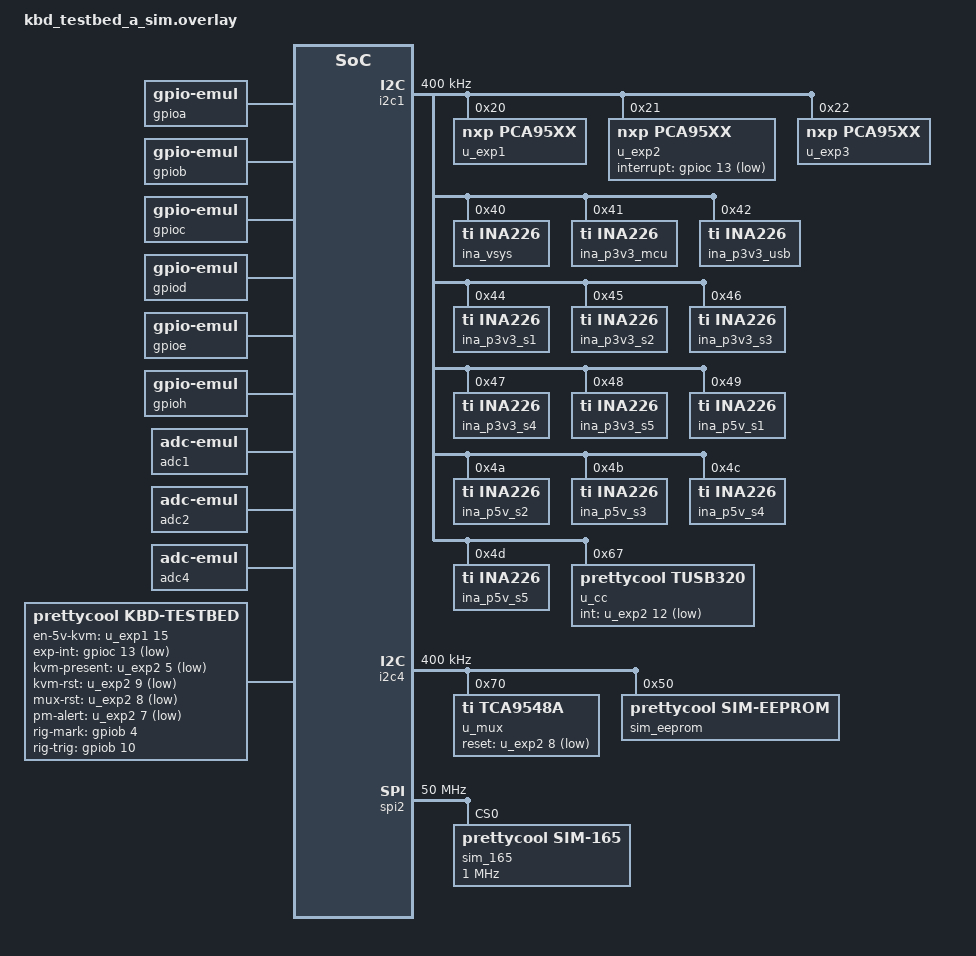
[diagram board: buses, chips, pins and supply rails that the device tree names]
/* GENERATED by keyboard/firmware/boards/gen_board.py from keyboard/hardware/design/nets.py
 * and the SPEC constants in that script. Do not edit: change nets.py (or the script), regenerate.
 * nets.py rev A-testbed 2026-11-27; map hash 10b5eaea9fcebc38.
 *
 * native_sim overlay: kbd_testbed_a's nodes on emulated controllers, for the bring-up app's simulated board
 * (keyboard/firmware/bringup/sim). Register models stand in for the parts: this tests firmware logic, not the
 * hardware. SPDX-License-Identifier: Apache-2.0
 */

#include <zephyr/dt-bindings/adc/adc.h>
#include <zephyr/dt-bindings/gpio/gpio.h>
#include <zephyr/dt-bindings/i2c/i2c.h>

/ {
	gpioa: sim_gpio_a {
		compatible = "zephyr,gpio-emul";
		rising-edge;
		falling-edge;
		high-level;
		low-level;
		gpio-controller;
		#gpio-cells = <2>;
		ngpios = <16>;
		status = "okay";
	};

	gpiob: sim_gpio_b {
		compatible = "zephyr,gpio-emul";
		rising-edge;
		falling-edge;
		high-level;
		low-level;
		gpio-controller;
		#gpio-cells = <2>;
		ngpios = <16>;
		status = "okay";
	};

	gpioc: sim_gpio_c {
		compatible = "zephyr,gpio-emul";
		rising-edge;
		falling-edge;
		high-level;
		low-level;
		gpio-controller;
		#gpio-cells = <2>;
		ngpios = <16>;
		status = "okay";
	};

	gpiod: sim_gpio_d {
		compatible = "zephyr,gpio-emul";
		rising-edge;
		falling-edge;
		high-level;
		low-level;
		gpio-controller;
		#gpio-cells = <2>;
		ngpios = <16>;
		status = "okay";
	};

	gpioe: sim_gpio_e {
		compatible = "zephyr,gpio-emul";
		rising-edge;
		falling-edge;
		high-level;
		low-level;
		gpio-controller;
		#gpio-cells = <2>;
		ngpios = <16>;
		status = "okay";
	};

	gpioh: sim_gpio_h {
		compatible = "zephyr,gpio-emul";
		rising-edge;
		falling-edge;
		high-level;
		low-level;
		gpio-controller;
		#gpio-cells = <2>;
		ngpios = <16>;
		status = "okay";
	};

	i2c1: i2c@71000 {
		compatible = "zephyr,i2c-emul-controller";
		reg = <0x71000 4>;
		clock-frequency = <I2C_BITRATE_FAST>;
		#address-cells = <1>;
		#size-cells = <0>;
		#forward-cells = <1>;
		status = "okay";

		/* U_EXP1 TCA9535 (rail enables, bus-switch enables). Restored outputs 0xFFFF, output register 0x7C00, configuration
		 * 0x0000. nxp,pca95xx with neither has-pud nor has-interrupt-mask-reg (SPEC §8.4). */
		u_exp1: gpio@20 {
			compatible = "nxp,pca95xx";
			reg = <0x20>;
			gpio-controller;
			#gpio-cells = <2>;
			ngpios = <16>;
		};

		/* U_EXP2 TCA9535 (PRESENT_N, faults, alerts, mux and KVM resets, the USB-C detect interrupt). Restored outputs 0x0300, output register 0xFDFF, configuration
		 * 0xFCFF. nxp,pca95xx with neither has-pud nor has-interrupt-mask-reg (SPEC §8.4). */
		u_exp2: gpio@21 {
			compatible = "nxp,pca95xx";
			reg = <0x21>;
			gpio-controller;
			#gpio-cells = <2>;
			ngpios = <16>;
			interrupt-gpios = <&gpioc 13 GPIO_ACTIVE_LOW>;
		};

		/* U_EXP3 TCA9535 (S1-S4 G4/G5, slot LEDs). Restored outputs 0x1FFF, output register 0xFF00, configuration
		 * 0xE000. nxp,pca95xx with neither has-pud nor has-interrupt-mask-reg (SPEC §8.4). */
		u_exp3: gpio@22 {
			compatible = "nxp,pca95xx";
			reg = <0x22>;
			gpio-controller;
			#gpio-cells = <2>;
			ngpios = <16>;
		};

		/* VSYS: 0.02 ohm shunt, current LSB 125 uA (CAL 2048), full scale 4096 mA. */
		ina_vsys: ina226@40 {
			compatible = "ti,ina226";
			reg = <0x40>;
			current-lsb-microamps = <125>;
			rshunt-micro-ohms = <20000>;
		};

		/* +3V3_MCU: 0.5 ohm shunt, current LSB 5 uA (CAL 2048), full scale 164 mA. */
		ina_p3v3_mcu: ina226@41 {
			compatible = "ti,ina226";
			reg = <0x41>;
			current-lsb-microamps = <5>;
			rshunt-micro-ohms = <500000>;
		};

		/* +3V3_USB: 1 ohm shunt, current LSB 3 uA (CAL 1707), full scale 82 mA. */
		ina_p3v3_usb: ina226@42 {
			compatible = "ti,ina226";
			reg = <0x42>;
			current-lsb-microamps = <3>;
			rshunt-micro-ohms = <1000000>;
		};

		/* +3V3_S1: 0.24 ohm shunt, current LSB 11 uA (CAL 1939), full scale 341 mA. */
		ina_p3v3_s1: ina226@44 {
			compatible = "ti,ina226";
			reg = <0x44>;
			current-lsb-microamps = <11>;
			rshunt-micro-ohms = <240000>;
		};

		/* +3V3_S2: 0.24 ohm shunt, current LSB 11 uA (CAL 1939), full scale 341 mA. */
		ina_p3v3_s2: ina226@45 {
			compatible = "ti,ina226";
			reg = <0x45>;
			current-lsb-microamps = <11>;
			rshunt-micro-ohms = <240000>;
		};

		/* +3V3_S3: 0.24 ohm shunt, current LSB 11 uA (CAL 1939), full scale 341 mA. */
		ina_p3v3_s3: ina226@46 {
			compatible = "ti,ina226";
			reg = <0x46>;
			current-lsb-microamps = <11>;
			rshunt-micro-ohms = <240000>;
		};

		/* +3V3_S4: 0.24 ohm shunt, current LSB 11 uA (CAL 1939), full scale 341 mA. */
		ina_p3v3_s4: ina226@47 {
			compatible = "ti,ina226";
			reg = <0x47>;
			current-lsb-microamps = <11>;
			rshunt-micro-ohms = <240000>;
		};

		/* +3V3_S5: 0.24 ohm shunt, current LSB 11 uA (CAL 1939), full scale 341 mA. */
		ina_p3v3_s5: ina226@48 {
			compatible = "ti,ina226";
			reg = <0x48>;
			current-lsb-microamps = <11>;
			rshunt-micro-ohms = <240000>;
		};

		/* +5V_S1: 0.1 ohm shunt, current LSB 25 uA (CAL 2048), full scale 819 mA. */
		ina_p5v_s1: ina226@49 {
			compatible = "ti,ina226";
			reg = <0x49>;
			current-lsb-microamps = <25>;
			rshunt-micro-ohms = <100000>;
		};

		/* +5V_S2: 0.1 ohm shunt, current LSB 25 uA (CAL 2048), full scale 819 mA. */
		ina_p5v_s2: ina226@4a {
			compatible = "ti,ina226";
			reg = <0x4a>;
			current-lsb-microamps = <25>;
			rshunt-micro-ohms = <100000>;
		};

		/* +5V_S3: 0.1 ohm shunt, current LSB 25 uA (CAL 2048), full scale 819 mA. */
		ina_p5v_s3: ina226@4b {
			compatible = "ti,ina226";
			reg = <0x4b>;
			current-lsb-microamps = <25>;
			rshunt-micro-ohms = <100000>;
		};

		/* +5V_S4: 0.1 ohm shunt, current LSB 25 uA (CAL 2048), full scale 819 mA. */
		ina_p5v_s4: ina226@4c {
			compatible = "ti,ina226";
			reg = <0x4c>;
			current-lsb-microamps = <25>;
			rshunt-micro-ohms = <100000>;
		};

		/* +5V_S5: 0.02 ohm shunt, current LSB 125 uA (CAL 2048), full scale 4096 mA. */
		ina_p5v_s5: ina226@4d {
			compatible = "ti,ina226";
			reg = <0x4d>;
			current-lsb-microamps = <125>;
			rshunt-micro-ohms = <20000>;
		};

		/* U_CC TUSB320LAIRWBR: Type-C source advertisement, read only (SPEC §3.8, §8.4). Its INT_N reaches
		 * the MCU through U_EXP2 (no MCU pin). Zephyr v4.5.0 has no driver for it. */
		u_cc: typec@67 {
			compatible = "prettycool,tusb320";
			reg = <0x67>;
			int-gpios = <&u_exp2 12 GPIO_ACTIVE_LOW>;
			i2c-ready-ms = <100>;
			decide-ms = <200>;
		};
	};

	i2c4: i2c@71004 {
		compatible = "zephyr,i2c-emul-controller";
		reg = <0x71004 4>;
		clock-frequency = <I2C_BITRATE_FAST>;
		#address-cells = <1>;
		#size-cells = <0>;
		#forward-cells = <1>;
		status = "okay";

		/* U_MUX TCA9548A: ch0-ch4 = S1-S5, ch5 = KVM, ch6/ch7 = test pads. The driver never pulses RESET (it only deasserts it) and starts
		 * its channel cache at 0 without writing the device: after a warm reset the board service deselects
		 * the mux itself (SPEC §3.5, §8.4). idle-disconnect: no channel stays selected between transfers. */
		u_mux: mux@70 {
			compatible = "ti,tca9548a";
			reg = <0x70>;
			#address-cells = <1>;
			#size-cells = <0>;
			reset-gpios = <&u_exp2 8 GPIO_ACTIVE_LOW>;
			i2c-mux-idle-disconnect;

			/* channel 0: S1 */
			mux_ch0: i2c@0 {
				reg = <0>;
				#address-cells = <1>;
				#size-cells = <0>;
			};

			/* channel 1: S2 */
			mux_ch1: i2c@1 {
				reg = <1>;
				#address-cells = <1>;
				#size-cells = <0>;
			};

			/* channel 2: S3 */
			mux_ch2: i2c@2 {
				reg = <2>;
				#address-cells = <1>;
				#size-cells = <0>;
			};

			/* channel 3: S4 */
			mux_ch3: i2c@3 {
				reg = <3>;
				#address-cells = <1>;
				#size-cells = <0>;
			};

			/* channel 4: S5 */
			mux_ch4: i2c@4 {
				reg = <4>;
				#address-cells = <1>;
				#size-cells = <0>;
			};

			/* channel 5: J_KVM */
			mux_ch5: i2c@5 {
				reg = <5>;
				#address-cells = <1>;
				#size-cells = <0>;
			};

			/* channel 6: test pads (U_CC's fallback home, SPEC §3.4) */
			mux_ch6: i2c@6 {
				reg = <6>;
				#address-cells = <1>;
				#size-cells = <0>;
			};

			/* channel 7: test pads */
			mux_ch7: i2c@7 {
				reg = <7>;
				#address-cells = <1>;
				#size-cells = <0>;
			};
		};

		/* every coupon's descriptor EEPROM, at 0x50 behind its mux channel: one model that
		 * answers for the selected channel's slot */
		sim_eeprom: eeprom@50 {
			compatible = "prettycool,sim-eeprom";
			reg = <0x50>;
		};
	};

	spi2: spi@72000 {
		compatible = "zephyr,spi-emul-controller";
		reg = <0x72000 4>;
		clock-frequency = <50000000>;
		#address-cells = <1>;
		#size-cells = <0>;
		status = "okay";

		/* the test coupon's SN74LV165A loopback, on whichever slot's bus switch is closed */
		sim_165: loopback@0 {
			compatible = "prettycool,sim-165";
			reg = <0>;
			spi-max-frequency = <1000000>;
		};
	};

	adc1: sim_adc_1 {
		compatible = "zephyr,adc-emul";
		nchannels = <24>;
		ref-internal-mv = <3300>;
		#io-channel-cells = <1>;
		#address-cells = <1>;
		#size-cells = <0>;
		status = "okay";

		channel@1 {
			reg = <1>;
			zephyr,gain = "ADC_GAIN_1";
			zephyr,reference = "ADC_REF_INTERNAL";
			zephyr,acquisition-time = <ADC_ACQ_TIME(ADC_ACQ_TIME_TICKS, 391)>;
			zephyr,resolution = <14>;
		};

		channel@2 {
			reg = <2>;
			zephyr,gain = "ADC_GAIN_1";
			zephyr,reference = "ADC_REF_INTERNAL";
			zephyr,acquisition-time = <ADC_ACQ_TIME(ADC_ACQ_TIME_TICKS, 391)>;
			zephyr,resolution = <14>;
		};

		channel@3 {
			reg = <3>;
			zephyr,gain = "ADC_GAIN_1";
			zephyr,reference = "ADC_REF_INTERNAL";
			zephyr,acquisition-time = <ADC_ACQ_TIME(ADC_ACQ_TIME_TICKS, 391)>;
			zephyr,resolution = <14>;
		};

		channel@4 {
			reg = <4>;
			zephyr,gain = "ADC_GAIN_1";
			zephyr,reference = "ADC_REF_INTERNAL";
			zephyr,acquisition-time = <ADC_ACQ_TIME(ADC_ACQ_TIME_TICKS, 391)>;
			zephyr,resolution = <14>;
		};

		channel@5 {
			reg = <5>;
			zephyr,gain = "ADC_GAIN_1";
			zephyr,reference = "ADC_REF_INTERNAL";
			zephyr,acquisition-time = <ADC_ACQ_TIME(ADC_ACQ_TIME_TICKS, 391)>;
			zephyr,resolution = <14>;
		};

		channel@6 {
			reg = <6>;
			zephyr,gain = "ADC_GAIN_1";
			zephyr,reference = "ADC_REF_INTERNAL";
			zephyr,acquisition-time = <ADC_ACQ_TIME(ADC_ACQ_TIME_TICKS, 391)>;
			zephyr,resolution = <14>;
		};

		channel@7 {
			reg = <7>;
			zephyr,gain = "ADC_GAIN_1";
			zephyr,reference = "ADC_REF_INTERNAL";
			zephyr,acquisition-time = <ADC_ACQ_TIME(ADC_ACQ_TIME_TICKS, 391)>;
			zephyr,resolution = <14>;
		};

		channel@8 {
			reg = <8>;
			zephyr,gain = "ADC_GAIN_1";
			zephyr,reference = "ADC_REF_INTERNAL";
			zephyr,acquisition-time = <ADC_ACQ_TIME(ADC_ACQ_TIME_TICKS, 391)>;
			zephyr,resolution = <14>;
		};

		channel@9 {
			reg = <9>;
			zephyr,gain = "ADC_GAIN_1";
			zephyr,reference = "ADC_REF_INTERNAL";
			zephyr,acquisition-time = <ADC_ACQ_TIME(ADC_ACQ_TIME_TICKS, 391)>;
			zephyr,resolution = <14>;
		};

		channel@a {
			reg = <10>;
			zephyr,gain = "ADC_GAIN_1";
			zephyr,reference = "ADC_REF_INTERNAL";
			zephyr,acquisition-time = <ADC_ACQ_TIME(ADC_ACQ_TIME_TICKS, 391)>;
			zephyr,resolution = <14>;
		};

		channel@b {
			reg = <11>;
			zephyr,gain = "ADC_GAIN_1";
			zephyr,reference = "ADC_REF_INTERNAL";
			zephyr,acquisition-time = <ADC_ACQ_TIME(ADC_ACQ_TIME_TICKS, 391)>;
			zephyr,resolution = <14>;
		};

		channel@c {
			reg = <12>;
			zephyr,gain = "ADC_GAIN_1";
			zephyr,reference = "ADC_REF_INTERNAL";
			zephyr,acquisition-time = <ADC_ACQ_TIME(ADC_ACQ_TIME_TICKS, 391)>;
			zephyr,resolution = <14>;
		};

		channel@d {
			reg = <13>;
			zephyr,gain = "ADC_GAIN_1";
			zephyr,reference = "ADC_REF_INTERNAL";
			zephyr,acquisition-time = <ADC_ACQ_TIME(ADC_ACQ_TIME_TICKS, 391)>;
			zephyr,resolution = <14>;
		};

		channel@e {
			reg = <14>;
			zephyr,gain = "ADC_GAIN_1";
			zephyr,reference = "ADC_REF_INTERNAL";
			zephyr,acquisition-time = <ADC_ACQ_TIME(ADC_ACQ_TIME_TICKS, 391)>;
			zephyr,resolution = <14>;
		};

		channel@f {
			reg = <15>;
			zephyr,gain = "ADC_GAIN_1";
			zephyr,reference = "ADC_REF_INTERNAL";
			zephyr,acquisition-time = <ADC_ACQ_TIME(ADC_ACQ_TIME_TICKS, 391)>;
			zephyr,resolution = <14>;
		};

		channel@10 {
			reg = <16>;
			zephyr,gain = "ADC_GAIN_1";
			zephyr,reference = "ADC_REF_INTERNAL";
			zephyr,acquisition-time = <ADC_ACQ_TIME(ADC_ACQ_TIME_TICKS, 391)>;
			zephyr,resolution = <14>;
		};

		channel@11 {
			reg = <17>;
			zephyr,gain = "ADC_GAIN_1";
			zephyr,reference = "ADC_REF_INTERNAL";
			zephyr,acquisition-time = <ADC_ACQ_TIME(ADC_ACQ_TIME_TICKS, 391)>;
			zephyr,resolution = <14>;
		};
	};

	adc2: sim_adc_2 {
		compatible = "zephyr,adc-emul";
		nchannels = <24>;
		ref-internal-mv = <3300>;
		#io-channel-cells = <1>;
		#address-cells = <1>;
		#size-cells = <0>;
		status = "okay";

		channel@1 {
			reg = <1>;
			zephyr,gain = "ADC_GAIN_1";
			zephyr,reference = "ADC_REF_INTERNAL";
			zephyr,acquisition-time = <ADC_ACQ_TIME(ADC_ACQ_TIME_TICKS, 391)>;
			zephyr,resolution = <14>;
		};

		channel@2 {
			reg = <2>;
			zephyr,gain = "ADC_GAIN_1";
			zephyr,reference = "ADC_REF_INTERNAL";
			zephyr,acquisition-time = <ADC_ACQ_TIME(ADC_ACQ_TIME_TICKS, 391)>;
			zephyr,resolution = <14>;
		};

		channel@3 {
			reg = <3>;
			zephyr,gain = "ADC_GAIN_1";
			zephyr,reference = "ADC_REF_INTERNAL";
			zephyr,acquisition-time = <ADC_ACQ_TIME(ADC_ACQ_TIME_TICKS, 391)>;
			zephyr,resolution = <14>;
		};

		channel@4 {
			reg = <4>;
			zephyr,gain = "ADC_GAIN_1";
			zephyr,reference = "ADC_REF_INTERNAL";
			zephyr,acquisition-time = <ADC_ACQ_TIME(ADC_ACQ_TIME_TICKS, 391)>;
			zephyr,resolution = <14>;
		};

		channel@5 {
			reg = <5>;
			zephyr,gain = "ADC_GAIN_1";
			zephyr,reference = "ADC_REF_INTERNAL";
			zephyr,acquisition-time = <ADC_ACQ_TIME(ADC_ACQ_TIME_TICKS, 391)>;
			zephyr,resolution = <14>;
		};

		channel@6 {
			reg = <6>;
			zephyr,gain = "ADC_GAIN_1";
			zephyr,reference = "ADC_REF_INTERNAL";
			zephyr,acquisition-time = <ADC_ACQ_TIME(ADC_ACQ_TIME_TICKS, 391)>;
			zephyr,resolution = <14>;
		};

		channel@7 {
			reg = <7>;
			zephyr,gain = "ADC_GAIN_1";
			zephyr,reference = "ADC_REF_INTERNAL";
			zephyr,acquisition-time = <ADC_ACQ_TIME(ADC_ACQ_TIME_TICKS, 391)>;
			zephyr,resolution = <14>;
		};

		channel@8 {
			reg = <8>;
			zephyr,gain = "ADC_GAIN_1";
			zephyr,reference = "ADC_REF_INTERNAL";
			zephyr,acquisition-time = <ADC_ACQ_TIME(ADC_ACQ_TIME_TICKS, 391)>;
			zephyr,resolution = <14>;
		};

		channel@9 {
			reg = <9>;
			zephyr,gain = "ADC_GAIN_1";
			zephyr,reference = "ADC_REF_INTERNAL";
			zephyr,acquisition-time = <ADC_ACQ_TIME(ADC_ACQ_TIME_TICKS, 391)>;
			zephyr,resolution = <14>;
		};

		channel@a {
			reg = <10>;
			zephyr,gain = "ADC_GAIN_1";
			zephyr,reference = "ADC_REF_INTERNAL";
			zephyr,acquisition-time = <ADC_ACQ_TIME(ADC_ACQ_TIME_TICKS, 391)>;
			zephyr,resolution = <14>;
		};

		channel@b {
			reg = <11>;
			zephyr,gain = "ADC_GAIN_1";
			zephyr,reference = "ADC_REF_INTERNAL";
			zephyr,acquisition-time = <ADC_ACQ_TIME(ADC_ACQ_TIME_TICKS, 391)>;
			zephyr,resolution = <14>;
		};

		channel@c {
			reg = <12>;
			zephyr,gain = "ADC_GAIN_1";
			zephyr,reference = "ADC_REF_INTERNAL";
			zephyr,acquisition-time = <ADC_ACQ_TIME(ADC_ACQ_TIME_TICKS, 391)>;
			zephyr,resolution = <14>;
		};

		channel@d {
			reg = <13>;
			zephyr,gain = "ADC_GAIN_1";
			zephyr,reference = "ADC_REF_INTERNAL";
			zephyr,acquisition-time = <ADC_ACQ_TIME(ADC_ACQ_TIME_TICKS, 391)>;
			zephyr,resolution = <14>;
		};

		channel@e {
			reg = <14>;
			zephyr,gain = "ADC_GAIN_1";
			zephyr,reference = "ADC_REF_INTERNAL";
			zephyr,acquisition-time = <ADC_ACQ_TIME(ADC_ACQ_TIME_TICKS, 391)>;
			zephyr,resolution = <14>;
		};

		channel@f {
			reg = <15>;
			zephyr,gain = "ADC_GAIN_1";
			zephyr,reference = "ADC_REF_INTERNAL";
			zephyr,acquisition-time = <ADC_ACQ_TIME(ADC_ACQ_TIME_TICKS, 391)>;
			zephyr,resolution = <14>;
		};

		channel@10 {
			reg = <16>;
			zephyr,gain = "ADC_GAIN_1";
			zephyr,reference = "ADC_REF_INTERNAL";
			zephyr,acquisition-time = <ADC_ACQ_TIME(ADC_ACQ_TIME_TICKS, 391)>;
			zephyr,resolution = <14>;
		};

		channel@11 {
			reg = <17>;
			zephyr,gain = "ADC_GAIN_1";
			zephyr,reference = "ADC_REF_INTERNAL";
			zephyr,acquisition-time = <ADC_ACQ_TIME(ADC_ACQ_TIME_TICKS, 391)>;
			zephyr,resolution = <14>;
		};
	};

	adc4: sim_adc_4 {
		compatible = "zephyr,adc-emul";
		nchannels = <24>;
		ref-internal-mv = <3300>;
		#io-channel-cells = <1>;
		#address-cells = <1>;
		#size-cells = <0>;
		status = "okay";

		channel@1 {
			reg = <1>;
			zephyr,gain = "ADC_GAIN_1";
			zephyr,reference = "ADC_REF_INTERNAL";
			zephyr,acquisition-time = <ADC_ACQ_TIME(ADC_ACQ_TIME_TICKS, 815)>;
			zephyr,resolution = <12>;
		};

		channel@2 {
			reg = <2>;
			zephyr,gain = "ADC_GAIN_1";
			zephyr,reference = "ADC_REF_INTERNAL";
			zephyr,acquisition-time = <ADC_ACQ_TIME(ADC_ACQ_TIME_TICKS, 815)>;
			zephyr,resolution = <12>;
		};

		channel@3 {
			reg = <3>;
			zephyr,gain = "ADC_GAIN_1";
			zephyr,reference = "ADC_REF_INTERNAL";
			zephyr,acquisition-time = <ADC_ACQ_TIME(ADC_ACQ_TIME_TICKS, 815)>;
			zephyr,resolution = <12>;
		};

		channel@4 {
			reg = <4>;
			zephyr,gain = "ADC_GAIN_1";
			zephyr,reference = "ADC_REF_INTERNAL";
			zephyr,acquisition-time = <ADC_ACQ_TIME(ADC_ACQ_TIME_TICKS, 815)>;
			zephyr,resolution = <12>;
		};

		channel@9 {
			reg = <9>;
			zephyr,gain = "ADC_GAIN_1";
			zephyr,reference = "ADC_REF_INTERNAL";
			zephyr,acquisition-time = <ADC_ACQ_TIME(ADC_ACQ_TIME_TICKS, 815)>;
			zephyr,resolution = <12>;
		};

		channel@a {
			reg = <10>;
			zephyr,gain = "ADC_GAIN_1";
			zephyr,reference = "ADC_REF_INTERNAL";
			zephyr,acquisition-time = <ADC_ACQ_TIME(ADC_ACQ_TIME_TICKS, 815)>;
			zephyr,resolution = <12>;
		};

		channel@b {
			reg = <11>;
			zephyr,gain = "ADC_GAIN_1";
			zephyr,reference = "ADC_REF_INTERNAL";
			zephyr,acquisition-time = <ADC_ACQ_TIME(ADC_ACQ_TIME_TICKS, 815)>;
			zephyr,resolution = <12>;
		};

		channel@f {
			reg = <15>;
			zephyr,gain = "ADC_GAIN_1";
			zephyr,reference = "ADC_REF_INTERNAL";
			zephyr,acquisition-time = <ADC_ACQ_TIME(ADC_ACQ_TIME_TICKS, 815)>;
			zephyr,resolution = <12>;
		};

		channel@10 {
			reg = <16>;
			zephyr,gain = "ADC_GAIN_1";
			zephyr,reference = "ADC_REF_INTERNAL";
			zephyr,acquisition-time = <ADC_ACQ_TIME(ADC_ACQ_TIME_TICKS, 815)>;
			zephyr,resolution = <12>;
		};

		channel@11 {
			reg = <17>;
			zephyr,gain = "ADC_GAIN_1";
			zephyr,reference = "ADC_REF_INTERNAL";
			zephyr,acquisition-time = <ADC_ACQ_TIME(ADC_ACQ_TIME_TICKS, 815)>;
			zephyr,resolution = <12>;
		};

		channel@12 {
			reg = <18>;
			zephyr,gain = "ADC_GAIN_1";
			zephyr,reference = "ADC_REF_INTERNAL";
			zephyr,acquisition-time = <ADC_ACQ_TIME(ADC_ACQ_TIME_TICKS, 815)>;
			zephyr,resolution = <12>;
		};

		channel@13 {
			reg = <19>;
			zephyr,gain = "ADC_GAIN_1";
			zephyr,reference = "ADC_REF_INTERNAL";
			zephyr,acquisition-time = <ADC_ACQ_TIME(ADC_ACQ_TIME_TICKS, 815)>;
			zephyr,resolution = <12>;
		};

		channel@14 {
			reg = <20>;
			zephyr,gain = "ADC_GAIN_1";
			zephyr,reference = "ADC_REF_INTERNAL";
			zephyr,acquisition-time = <ADC_ACQ_TIME(ADC_ACQ_TIME_TICKS, 815)>;
			zephyr,resolution = <12>;
		};

		channel@16 {
			reg = <22>;
			zephyr,gain = "ADC_GAIN_1";
			zephyr,reference = "ADC_REF_INTERNAL";
			zephyr,acquisition-time = <ADC_ACQ_TIME(ADC_ACQ_TIME_TICKS, 815)>;
			zephyr,resolution = <12>;
		};

		channel@17 {
			reg = <23>;
			zephyr,gain = "ADC_GAIN_1";
			zephyr,reference = "ADC_REF_INTERNAL";
			zephyr,acquisition-time = <ADC_ACQ_TIME(ADC_ACQ_TIME_TICKS, 815)>;
			zephyr,resolution = <12>;
		};
	};

	/* The motherboard's own signals (SPEC §3, §4.3, §7.3), for the board service and the bring-up app. */
	testbed: testbed {
		compatible = "prettycool,kbd-testbed";
		en-5v-kvm-gpios = <&u_exp1 15 GPIO_ACTIVE_HIGH>;
		exp-int-gpios = <&gpioc 13 GPIO_ACTIVE_LOW>;
		kvm-present-gpios = <&u_exp2 5 GPIO_ACTIVE_LOW>;
		kvm-rst-gpios = <&u_exp2 9 GPIO_ACTIVE_LOW>;
		mux-rst-gpios = <&u_exp2 8 GPIO_ACTIVE_LOW>;
		pm-alert-gpios = <&u_exp2 7 GPIO_ACTIVE_LOW>;
		rig-mark-gpios = <&gpiob 4 GPIO_ACTIVE_HIGH>;
		rig-trig-gpios = <&gpiob 10 GPIO_ACTIVE_HIGH>;
		s5-pg-gpios = <&u_exp2 11 GPIO_ACTIVE_HIGH>;
		slot-fault-gpios = <&u_exp2 6 GPIO_ACTIVE_LOW>;
		slot-sync-gpios = <&gpioa 15 GPIO_ACTIVE_HIGH>;
		usbc-int-gpios = <&u_exp2 12 GPIO_ACTIVE_LOW>;
		vsys-pg-gpios = <&u_exp2 10 GPIO_ACTIVE_HIGH>;
		ina226-vsys = <&ina_vsys>;
		ina226-mcu = <&ina_p3v3_mcu>;
		ina226-usb = <&ina_p3v3_usb>;
		typec = <&u_cc>;
		slot-mux = <&u_mux>;
		kvm-i2c = <&mux_ch5>;
		slot-ldo-milliamps = <300>;
		base-load-milliamps = <45>;
		vsys-budget-max-milliamps = <2800>;
		vsys-budget-unconfigured-milliamps = <100>;
		vsys-trip-milliamps = <2960 3330 3620>;
		kvm-trip-milliamps = <519 577 644>;
		kvm-rule-milliamps = <500>;
	};

	/* The five coupon slots (SPEC §4.2-§4.4). Lanes: io-channels = AN0..AN3 on their primary converter;
	 * alt-adc-channels = <lane adc channel> for every other converter that reaches the lane's pin. */
	slots {
		slot1: slot-1 {
			compatible = "prettycool,coupon-slot";
			slot = <1>;
			io-channels = <&adc1 1>, <&adc1 2>, <&adc1 3>, <&adc1 4>;
			io-channel-names = "AN0", "AN1", "AN2", "AN3";
			alt-adc-channels = <0 2 1  0 4 1  1 2 2  1 4 2  2 2 3  2 4 3  3 2 4  3 4 4>;
			g-gpios = <&gpioe 2 GPIO_ACTIVE_HIGH>, <&gpioe 3 GPIO_ACTIVE_HIGH>, <&gpioe 4 GPIO_ACTIVE_HIGH>, <&gpioe 5 GPIO_ACTIVE_HIGH>, <&u_exp3 0 GPIO_ACTIVE_HIGH>, <&u_exp3 1 GPIO_ACTIVE_HIGH>;
			cs-gpios = <&gpioe 6 GPIO_ACTIVE_LOW>, <&gpioe 1 GPIO_ACTIVE_LOW>;
			irq-gpios = <&gpioc 14 GPIO_ACTIVE_LOW>;
			present-gpios = <&u_exp2 0 GPIO_ACTIVE_LOW>;
			en-3v3-gpios = <&u_exp1 0 GPIO_ACTIVE_HIGH>;
			en-5v-gpios = <&u_exp1 5 GPIO_ACTIVE_HIGH>;
			busen-gpios = <&u_exp1 10 GPIO_ACTIVE_LOW>;
			led-gpios = <&u_exp3 8 GPIO_ACTIVE_LOW>;
			ina226-3v3 = <&ina_p3v3_s1>;
			ina226-5v = <&ina_p5v_s1>;
			i2c-channel = <&mux_ch0>;
			rule-3v3-milliamps = <250>;
			rule-5v-milliamps = <500>;
			trip-3v3-milliamps = <256 292 335>;
			trip-5v-milliamps = <519 577 644>;
			rail-3v3 = <0>;
			rail-5v = <5>;
		};

		slot2: slot-2 {
			compatible = "prettycool,coupon-slot";
			slot = <2>;
			io-channels = <&adc1 5>, <&adc1 6>, <&adc1 7>, <&adc1 8>;
			io-channel-names = "AN0", "AN1", "AN2", "AN3";
			alt-adc-channels = <0 2 5  1 2 6  2 2 7  3 2 8>;
			g-gpios = <&gpiod 8 GPIO_ACTIVE_HIGH>, <&gpiod 9 GPIO_ACTIVE_HIGH>, <&gpiod 10 GPIO_ACTIVE_HIGH>, <&gpiod 14 GPIO_ACTIVE_HIGH>, <&u_exp3 2 GPIO_ACTIVE_HIGH>, <&u_exp3 3 GPIO_ACTIVE_HIGH>;
			cs-gpios = <&gpiod 15 GPIO_ACTIVE_LOW>, <&gpiod 7 GPIO_ACTIVE_LOW>;
			irq-gpios = <&gpiod 6 GPIO_ACTIVE_LOW>;
			present-gpios = <&u_exp2 1 GPIO_ACTIVE_LOW>;
			en-3v3-gpios = <&u_exp1 1 GPIO_ACTIVE_HIGH>;
			en-5v-gpios = <&u_exp1 6 GPIO_ACTIVE_HIGH>;
			busen-gpios = <&u_exp1 11 GPIO_ACTIVE_LOW>;
			led-gpios = <&u_exp3 9 GPIO_ACTIVE_LOW>;
			ina226-3v3 = <&ina_p3v3_s2>;
			ina226-5v = <&ina_p5v_s2>;
			i2c-channel = <&mux_ch1>;
			rule-3v3-milliamps = <250>;
			rule-5v-milliamps = <500>;
			trip-3v3-milliamps = <256 292 335>;
			trip-5v-milliamps = <519 577 644>;
			rail-3v3 = <1>;
			rail-5v = <6>;
		};

		slot3: slot-3 {
			compatible = "prettycool,coupon-slot";
			slot = <3>;
			io-channels = <&adc1 9>, <&adc1 10>, <&adc1 11>, <&adc1 12>;
			io-channel-names = "AN0", "AN1", "AN2", "AN3";
			alt-adc-channels = <0 2 9  0 4 9  1 2 10  1 4 10  2 2 11  2 4 11  3 2 12  3 4 20>;
			g-gpios = <&gpiod 0 GPIO_ACTIVE_HIGH>, <&gpiod 1 GPIO_ACTIVE_HIGH>, <&gpiod 2 GPIO_ACTIVE_HIGH>, <&gpiod 3 GPIO_ACTIVE_HIGH>, <&u_exp3 4 GPIO_ACTIVE_HIGH>, <&u_exp3 5 GPIO_ACTIVE_HIGH>;
			cs-gpios = <&gpiod 4 GPIO_ACTIVE_LOW>, <&gpiod 5 GPIO_ACTIVE_LOW>;
			irq-gpios = <&gpioe 0 GPIO_ACTIVE_LOW>;
			present-gpios = <&u_exp2 2 GPIO_ACTIVE_LOW>;
			en-3v3-gpios = <&u_exp1 2 GPIO_ACTIVE_HIGH>;
			en-5v-gpios = <&u_exp1 7 GPIO_ACTIVE_HIGH>;
			busen-gpios = <&u_exp1 12 GPIO_ACTIVE_LOW>;
			led-gpios = <&u_exp3 10 GPIO_ACTIVE_LOW>;
			ina226-3v3 = <&ina_p3v3_s3>;
			ina226-5v = <&ina_p5v_s3>;
			i2c-channel = <&mux_ch2>;
			rule-3v3-milliamps = <250>;
			rule-5v-milliamps = <500>;
			trip-3v3-milliamps = <256 292 335>;
			trip-5v-milliamps = <519 577 644>;
			rail-3v3 = <2>;
			rail-5v = <7>;
		};

		slot4: slot-4 {
			compatible = "prettycool,coupon-slot";
			slot = <4>;
			io-channels = <&adc1 13>, <&adc1 14>, <&adc1 15>, <&adc1 16>;
			io-channel-names = "AN0", "AN1", "AN2", "AN3";
			alt-adc-channels = <0 2 13  0 4 22  1 2 14  1 4 23  2 2 15  2 4 18  3 2 16  3 4 19>;
			g-gpios = <&gpioc 6 GPIO_ACTIVE_HIGH>, <&gpioc 7 GPIO_ACTIVE_HIGH>, <&gpioc 8 GPIO_ACTIVE_HIGH>, <&gpioc 9 GPIO_ACTIVE_HIGH>, <&u_exp3 6 GPIO_ACTIVE_HIGH>, <&u_exp3 7 GPIO_ACTIVE_HIGH>;
			cs-gpios = <&gpiob 12 GPIO_ACTIVE_LOW>, <&gpioc 12 GPIO_ACTIVE_LOW>;
			irq-gpios = <&gpiob 5 GPIO_ACTIVE_LOW>;
			present-gpios = <&u_exp2 3 GPIO_ACTIVE_LOW>;
			en-3v3-gpios = <&u_exp1 3 GPIO_ACTIVE_HIGH>;
			en-5v-gpios = <&u_exp1 8 GPIO_ACTIVE_HIGH>;
			busen-gpios = <&u_exp1 13 GPIO_ACTIVE_LOW>;
			led-gpios = <&u_exp3 11 GPIO_ACTIVE_LOW>;
			ina226-3v3 = <&ina_p3v3_s4>;
			ina226-5v = <&ina_p5v_s4>;
			i2c-channel = <&mux_ch3>;
			rule-3v3-milliamps = <250>;
			rule-5v-milliamps = <500>;
			trip-3v3-milliamps = <256 292 335>;
			trip-5v-milliamps = <519 577 644>;
			rail-3v3 = <3>;
			rail-5v = <8>;
		};

		slot5: slot-5 {
			compatible = "prettycool,coupon-slot";
			slot = <5>;
			io-channels = <&adc1 17>, <&adc4 15>, <&adc4 16>, <&adc4 17>;
			io-channel-names = "AN0", "AN1", "AN2", "AN3";
			alt-adc-channels = <0 2 17>;
			g-gpios = <&gpioe 9 GPIO_ACTIVE_HIGH>, <&gpioe 11 GPIO_ACTIVE_HIGH>, <&gpioe 13 GPIO_ACTIVE_HIGH>, <&gpioe 8 GPIO_ACTIVE_HIGH>, <&gpioe 10 GPIO_ACTIVE_HIGH>, <&gpioe 12 GPIO_ACTIVE_HIGH>;
			cs-gpios = <&gpioe 14 GPIO_ACTIVE_LOW>, <&gpioe 7 GPIO_ACTIVE_LOW>;
			irq-gpios = <&gpioe 15 GPIO_ACTIVE_LOW>;
			/* TIM1_BKIN: never gpio_pin_configure() it while TIM1 runs (SPEC §5.3). */
			irq-is-tim1-bkin;
			present-gpios = <&u_exp2 4 GPIO_ACTIVE_LOW>;
			en-3v3-gpios = <&u_exp1 4 GPIO_ACTIVE_HIGH>;
			en-5v-gpios = <&u_exp1 9 GPIO_ACTIVE_HIGH>;
			busen-gpios = <&u_exp1 14 GPIO_ACTIVE_LOW>;
			led-gpios = <&u_exp3 12 GPIO_ACTIVE_LOW>;
			pg-5v-gpios = <&u_exp2 11 GPIO_ACTIVE_HIGH>;
			ina226-3v3 = <&ina_p3v3_s5>;
			ina226-5v = <&ina_p5v_s5>;
			i2c-channel = <&mux_ch4>;
			rule-3v3-milliamps = <250>;
			rule-5v-milliamps = <2000>;
			trip-3v3-milliamps = <256 292 335>;
			trip-5v-milliamps = <2010 2270 2460>;
			rail-3v3 = <4>;
			rail-5v = <9>;
		};
	};
};
